# ATxmega16E5 device description
Architecture: AVR8_XMEGA; Family: AVR XMEGA
Registers are 8-bit, access not given, no defined reset value unless marked. A register's access mark holds for its fields unless they carry their own. Offsets are from the block's base; [hi:lo] are bit positions; {n}, {i} and the like mark numbered series; 'fields as' and 'values as' point back to an identical list.

## TC4 — 16-bit Timer/Counter 4
Instances: TCC4 0x800
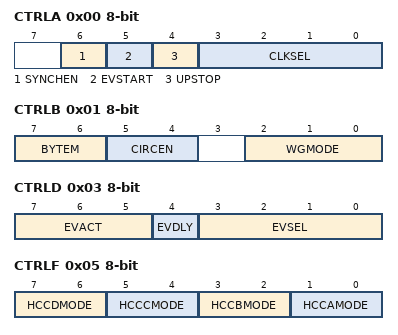
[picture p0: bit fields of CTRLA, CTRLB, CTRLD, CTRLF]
0x00 CTRLA — Control Register A
  [6] SYNCHEN — Synchronization Enabled
  [5] EVSTART — Start on Next Event
  [4] UPSTOP — Stop on Next Update
  [3:0] CLKSEL — Clock Select
    0=OFF (Timer Off); 1=DIV1 (System Clock); 2=DIV2 (System Clock / 2); 3=DIV4 (System Clock / 4); 4=DIV8 (System Clock / 8); 5=DIV64 (System Clock / 64); 6=DIV256 (System Clock / 256); 7=DIV1024 (System Clock / 1024); {v}=EVCH{v-8} (Event Channel {v-8}) (v=8..15)
0x01 CTRLB — Control Register B
  [7:6] BYTEM — Byte Mode
    0=NORMAL (16-bit mode); 1=BYTEMODE (Timer/Counter Operating in Byte Mode Only)
  [5:4] CIRCEN — Circular Buffer Enable
    0=DISABLE (Circular Buffer Disabled); 1=PER (Circular Buffer Enabled on PER/PERBUF); 2=CCA (Circular Buffer Enabled on CCA/CCABUF); 3=BOTH (Circular Buffer Enabled on All Buffered Registers)
  [2:0] WGMODE — Waveform Generation Mode
    0=NORMAL (Normal Mode); 1=FRQ (Frequency Generation Mode); 3=SINGLESLOPE; 5=DSTOP (Dual Slope, Update on TOP); 6=DSBOTH (Dual Slope, Both); 7=DSBOTTOM (Dual Slope, Update on BOTTOM)
0x02 CTRLC — Control register C
  [7] POLD — Channel D Output Polarity
  [7] HCMPD — High Channel D Compare Output Value
  [6] POLC — Channel C Output Polarity
  [6] HCMPC — High Channel C Compare Output Value
  [5] POLB — Channel B Output Polarity
  [5] HCMPB — High Channel B Compare Output Value
  [4] POLA — Channel A Output Polarity
  [4] HCMPA — High Channel A Compare Output Value
  [3] CMPD — Channel D Compare Output Value
  [3] LCMPD — Low Channel D Compare Output Value
  [2] CMPC — Channel C Compare Output Value
  [2] LCMPC — Low Channel C Compare Output Value
  [1] CMPB — Channel B Compare Output Value
  [1] LCMPB — Low Channel B Compare Output Value
  [0] CMPA — Channel A Compare Output Value
  [0] LCMPA — Low Channel A Compare Output Value
0x03 CTRLD — Control Register D
  [7:5] EVACT — Event Action
    0=OFF (No Event Action); 1=FMODE1 (Fault Mode 1 capture); 2=FMODE2 (Fault Mode 2 capture); 3=UPDOWN (Up/down count); 4=QDEC (Quadrature decode); 5=RESTART; 6=PWF (Pulse-width Capture)
  [4] EVDLY — Event Delay
  [3:0] EVSEL — Event Source Select
    0=OFF (No Event Source); {v}=CH{v-8} (Event Channel {v-8}) (v=8..15)
0x04 CTRLE — Control Register E
  [all] fields
    0=DISABLE (Channel Disabled); 1=COMP (Output Compare enabled); 2=CAPT (Input Capture enabled); 3=BOTHCC (Both Compare and Capture enabled)
  [7:6] CCDMODE — Channel D Compare or Capture Mode
  [7:6] LCCDMODE — Channel Low D Compare or Capture Mode
  [5:4] CCCMODE — Channel C Compare or Capture Mode
  [5:4] LCCCMODE — Channel Low C Compare or Capture Mode
  [3:2] CCBMODE — Channel B Compare or Capture Mode
  [3:2] LCCBMODE — Channel Low B Compare or Capture Mode
  [1:0] CCAMODE — Channel A Compare or Capture Mode
  [1:0] LCCAMODE — Channel Low A Compare or Capture Mode
0x05 CTRLF — Control Register F
  [all] fields
    values as the fields of CTRLE
  [7:6] HCCDMODE — Channel High D Compare or Capture Mode
  [5:4] HCCCMODE — Channel High C Compare or Capture Mode
  [3:2] HCCBMODE — Channel High B Compare or Capture Mode
  [1:0] HCCAMODE — Channel High A Compare or Capture Mode
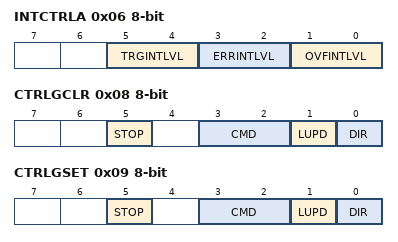
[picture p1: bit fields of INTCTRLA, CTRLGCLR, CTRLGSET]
0x06 INTCTRLA — Interrupt Control Register A
  [all] fields
    0=OFF (Interrupt Disabled); 1=LO (Low Level); 2=MED (Medium Level); 3=HI (High Level)
  [5:4] TRGINTLVL — Timer Trigger Restart Interrupt Level
  [3:2] ERRINTLVL — Timer Error Interrupt Level
  [1:0] OVFINTLVL — Timer Overflow/Underflow Interrupt Level
0x07 INTCTRLB — Interrupt Control Register B
  [all] fields
    values as the fields of INTCTRLA
  [7:6] CCDINTLVL — Channel D Compare or Capture Interrupt Level
  [7:6] LCCDINTLVL — Channel Low D Compare or Capture Interrupt Level
  [5:4] CCCINTLVL — Channel C Compare or Capture Interrupt Level
  [5:4] LCCCINTLVL — Channel Low C Compare or Capture Interrupt Level
  [3:2] CCBINTLVL — Channel B Compare or Capture Interrupt Level
  [3:2] LCCBINTLVL — Channel Low B Compare or Capture Interrupt Level
  [1:0] CCAINTLVL — Channel A Compare or Capture Interrupt Level
  [1:0] LCCAINTLVL — Channel Low A Compare or Capture Interrupt Level
0x08 CTRLGCLR — Control Register G Clear
  [5] STOP — Timer/Counter Stop
  [3:2] CMD — Command
    0=NONE (No Command); 1=UPDATE (Force Update); 2=RESTART (Force Restart); 3=RESET (Force Hard Reset)
  [1] LUPD — Lock Update
  [0] DIR — Counter Direction
0x09 CTRLGSET — Control Register G Set
  fields as CTRLGCLR
0x0A CTRLHCLR — Control Register H Clear
  [4] CCDBV — Channel D Compare or Capture Buffer Valid
  [4] LCCDBV — Channel Low D Compare or Capture Buffer Valid
  [3] CCCBV — Channel C Compare or Capture Buffer Valid
  [3] LCCCBV — Channel Low C Compare or Capture Buffer Valid
  [2] CCBBV — Channel B Compare or Capture Buffer Valid
  [2] LCCBBV — Channel Low B Compare or Capture Buffer Valid
  [1] CCABV — Channel A Compare or Capture Buffer Valid
  [1] LCCABV — Channel Low A Compare or Capture Buffer Valid
  [0] PERBV — Period Buffer Valid
  [0] LPERBV — Period Low Buffer Valid
0x0B CTRLHSET — Control Register H Set
  fields as CTRLHCLR
0x0C INTFLAGS — Interrupt Flag Register
  [7] CCDIF — Channel D Compare or Capture Interrupt Flag
  [7] LCCDIF — Channel Low D Compare or Capture Interrupt Flag
  [6] CCCIF — Channel C Compare or Capture Interrupt Flag
  [6] LCCCIF — Channel Low C Compare or Capture Interrupt Flag
  [5] CCBIF — Channel B Compare or Capture Interrupt Flag
  [5] LCCBIF — Channel Low B Compare or Capture Interrupt Flag
  [4] CCAIF — Channel A Compare or Capture Interrupt Flag
  [4] LCCAIF — Channel Low A Compare or Capture Interrupt Flag
  [2] TRGIF — Trigger Restart Interrupt Flag
  [1] ERRIF — Error Interrupt Flag
  [0] OVFIF — Overflow/Underflow Interrupt Flag
0x0F TEMP — Temporary Register For 16-bit Access
0x20 CNT 16-bit — Count
0x26 PER 16-bit — Period
0x28 CCA 16-bit — Compare or Capture A
0x2A CCB 16-bit — Compare or Capture B
0x2C CCC 16-bit — Compare or Capture C
0x2E CCD 16-bit — Compare or Capture D
0x36 PERBUF 16-bit — Period Buffer
0x38 CCABUF 16-bit — Compare Or Capture A Buffer
0x3A CCBBUF 16-bit — Compare Or Capture B Buffer
0x3C CCCBUF 16-bit — Compare Or Capture C Buffer
0x3E CCDBUF 16-bit — Compare Or Capture D Buffer
